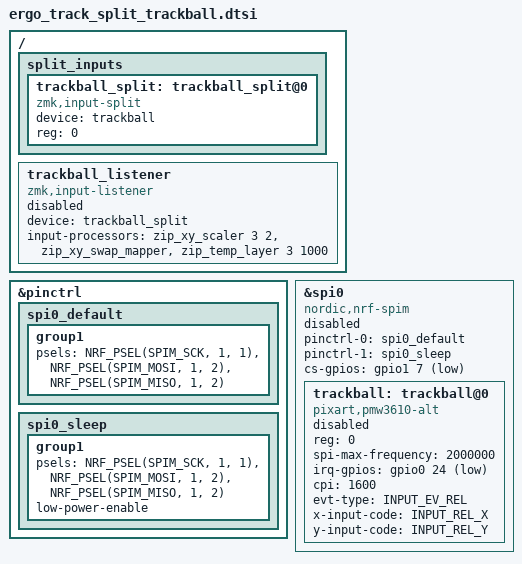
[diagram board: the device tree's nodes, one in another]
/*
 * Copyright (c) 2024
 * SPDX-License-Identifier: MIT
 */

#include <zephyr/dt-bindings/input/input-event-codes.h>
#include <input/processors.dtsi>

&pinctrl {
    spi0_default: spi0_default {
        group1 {
            psels = <NRF_PSEL(SPIM_SCK, 1, 1)>,
                    <NRF_PSEL(SPIM_MOSI, 1, 2)>,
                    <NRF_PSEL(SPIM_MISO, 1, 2)>;
        };
    };

    spi0_sleep: spi0_sleep {
        group1 {
            psels = <NRF_PSEL(SPIM_SCK, 1, 1)>,
                    <NRF_PSEL(SPIM_MOSI, 1, 2)>,
                    <NRF_PSEL(SPIM_MISO, 1, 2)>;
            low-power-enable;
        };
    };
};

&spi0 {
    status = "disabled";
    compatible = "nordic,nrf-spim";
    pinctrl-0 = <&spi0_default>;
    pinctrl-1 = <&spi0_sleep>;
    pinctrl-names = "default", "sleep";
    cs-gpios = <&gpio1 7 GPIO_ACTIVE_LOW>;

    trackball: trackball@0 {
        status = "disabled";
        compatible = "pixart,pmw3610-alt";
        reg = <0>;
        spi-max-frequency = <2000000>;
        irq-gpios = <&gpio0 24 (GPIO_ACTIVE_LOW | GPIO_PULL_UP)>;
        cpi = <1600>;
        evt-type = <INPUT_EV_REL>;
        x-input-code = <INPUT_REL_X>;
        y-input-code = <INPUT_REL_Y>;
    };
};

/ {
    split_inputs {
        #address-cells = <1>;
        #size-cells = <0>;

        trackball_split: trackball_split@0 {
            device = <&trackball>;
            compatible = "zmk,input-split";
            reg = <0>;
        };
    };

    trackball_listener: trackball_listener {
        compatible = "zmk,input-listener";
        status = "disabled";
        device = <&trackball_split>;
        input-processors = <&zip_xy_scaler 3 2 &zip_xy_swap_mapper &zip_temp_layer 3 1000>;
    };
};
